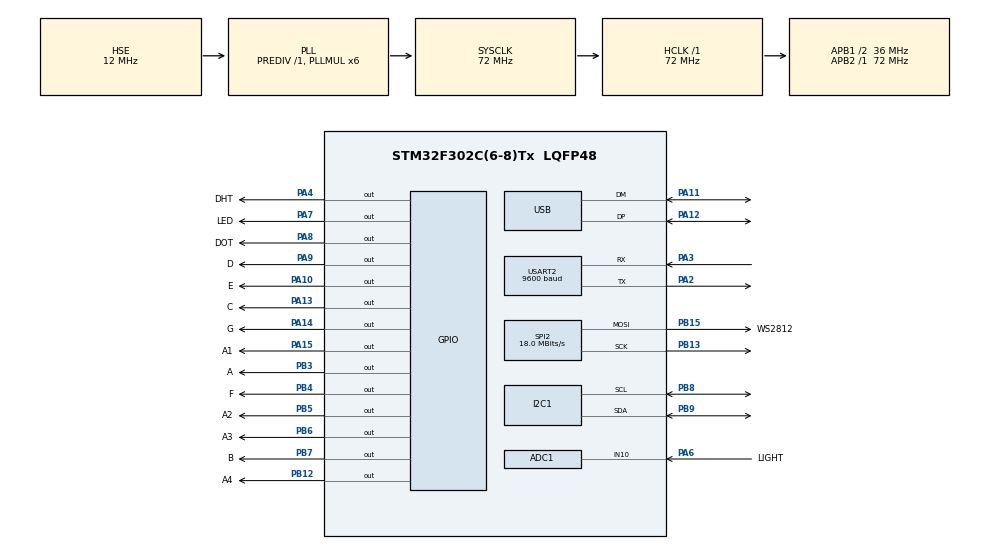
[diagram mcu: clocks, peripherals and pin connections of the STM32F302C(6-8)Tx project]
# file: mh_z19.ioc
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ADC1.Channel-0\#ChannelRegularConversion=ADC_CHANNEL_10
ADC1.NbrOfConversionFlag=1
ADC1.Offset-0\#ChannelRegularConversion=0
ADC1.OffsetNumber-0\#ChannelRegularConversion=ADC_OFFSET_NONE
ADC1.Rank-0\#ChannelRegularConversion=1
ADC1.SamplingTime-0\#ChannelRegularConversion=ADC_SAMPLETIME_1CYCLE_5
ADC1.SamplingTimeOPAMP-0\#ChannelRegularConversion=ADC_SAMPLETIME_19CYCLES_5
ADC1.SubFamily=STM32F302x8
ADC1.master=1
Dma.Request0=SPI2_TX
Dma.Request1=USART2_TX
Dma.SPI2_TX.0.Direction=DMA_MEMORY_TO_PERIPH
Dma.SPI2_TX.0.Instance=DMA1_Channel5
Dma.SPI2_TX.0.MemDataAlignment=DMA_MDATAALIGN_BYTE
Dma.SPI2_TX.0.MemInc=DMA_MINC_ENABLE
Dma.SPI2_TX.0.Mode=DMA_NORMAL
Dma.SPI2_TX.0.PeriphDataAlignment=DMA_PDATAALIGN_BYTE
Dma.SPI2_TX.0.PeriphInc=DMA_PINC_DISABLE
Dma.SPI2_TX.0.Priority=DMA_PRIORITY_LOW
Dma.USART2_TX.1.Direction=DMA_MEMORY_TO_PERIPH
Dma.USART2_TX.1.Instance=DMA1_Channel7
Dma.USART2_TX.1.MemDataAlignment=DMA_MDATAALIGN_BYTE
Dma.USART2_TX.1.MemInc=DMA_MINC_ENABLE
Dma.USART2_TX.1.Mode=DMA_NORMAL
Dma.USART2_TX.1.PeriphDataAlignment=DMA_PDATAALIGN_BYTE
Dma.USART2_TX.1.PeriphInc=DMA_PINC_DISABLE
Dma.USART2_TX.1.Priority=DMA_PRIORITY_LOW
I2C1.Timing=0x00201D2B
Mcu.Family=STM32F3
Mcu.Name=STM32F302C(6-8)Tx
Mcu.Package=LQFP48
NVIC.DMA1_Channel5_IRQn=true\:0\:0\:false\:false\:true\:false\:true\:true
NVIC.DMA1_Channel7_IRQn=true\:0\:0\:false\:false\:true\:false\:true\:true
NVIC.PriorityGroup=NVIC_PRIORITYGROUP_4
NVIC.USB_LP_CAN_RX0_IRQn=true\:0\:0\:false\:false\:true\:false\:true\:true
PA10.GPIO_Label=E
PA10.GPIO_ModeDefaultOutputPP=GPIO_MODE_OUTPUT_OD
PA10.GPIO_Speed=GPIO_SPEED_FREQ_HIGH
PA10.PinState=GPIO_PIN_SET
PA10.Signal=GPIO_Output
PA11.Mode=Device
PA11.Signal=USB_DM
PA12.Mode=Device
PA12.Signal=USB_DP
PA13.GPIO_Label=C
PA13.GPIO_ModeDefaultOutputPP=GPIO_MODE_OUTPUT_OD
PA13.PinState=GPIO_PIN_SET
PA13.Signal=GPIO_Output
PA14.GPIO_Label=G
PA14.GPIO_ModeDefaultOutputPP=GPIO_MODE_OUTPUT_OD
PA14.PinState=GPIO_PIN_SET
PA14.Signal=GPIO_Output
PA15.GPIO_Label=A1
PA15.GPIO_ModeDefaultOutputPP=GPIO_MODE_OUTPUT_OD
PA15.GPIO_Speed=GPIO_SPEED_FREQ_HIGH
PA15.PinState=GPIO_PIN_SET
PA15.Signal=GPIO_Output
PA2.Mode=Asynchronous
PA2.Signal=USART2_TX
PA3.Mode=Asynchronous
PA3.Signal=USART2_RX
PA4.GPIO_Label=DHT
PA4.GPIO_ModeDefaultOutputPP=GPIO_MODE_OUTPUT_OD
PA4.Signal=GPIO_Output
PA6.GPIO_Label=LIGHT
PA6.Signal=ADCx_IN10
PA7.GPIO_Label=LED
PA7.Signal=GPIO_Output
PA8.GPIO_Label=DOT
PA8.GPIO_ModeDefaultOutputPP=GPIO_MODE_OUTPUT_OD
PA8.GPIO_Speed=GPIO_SPEED_FREQ_HIGH
PA8.PinState=GPIO_PIN_SET
PA8.Signal=GPIO_Output
PA9.GPIO_Label=D
PA9.GPIO_ModeDefaultOutputPP=GPIO_MODE_OUTPUT_OD
PA9.GPIO_Speed=GPIO_SPEED_FREQ_HIGH
PA9.PinState=GPIO_PIN_SET
PA9.Signal=GPIO_Output
PB12.GPIO_Label=A4
PB12.GPIO_Speed=GPIO_SPEED_FREQ_HIGH
PB12.Signal=GPIO_Output
PB13.Mode=TX_Only_Simplex_Unidirect_Master
PB13.Signal=SPI2_SCK
PB15.GPIO_Label=WS2812
PB15.Mode=TX_Only_Simplex_Unidirect_Master
PB15.Signal=SPI2_MOSI
PB3.GPIO_Label=A
PB3.GPIO_ModeDefaultOutputPP=GPIO_MODE_OUTPUT_OD
PB3.GPIO_Speed=GPIO_SPEED_FREQ_HIGH
PB3.PinState=GPIO_PIN_SET
PB3.Signal=GPIO_Output
PB4.GPIO_Label=F
PB4.GPIO_ModeDefaultOutputPP=GPIO_MODE_OUTPUT_OD
PB4.GPIO_Speed=GPIO_SPEED_FREQ_HIGH
PB4.PinState=GPIO_PIN_SET
PB4.Signal=GPIO_Output
PB5.GPIO_Label=A2
PB5.GPIO_ModeDefaultOutputPP=GPIO_MODE_OUTPUT_OD
PB5.GPIO_Speed=GPIO_SPEED_FREQ_HIGH
PB5.PinState=GPIO_PIN_SET
PB5.Signal=GPIO_Output
PB6.GPIO_Label=A3
PB6.GPIO_ModeDefaultOutputPP=GPIO_MODE_OUTPUT_OD
PB6.GPIO_Speed=GPIO_SPEED_FREQ_HIGH
PB6.PinState=GPIO_PIN_SET
PB6.Signal=GPIO_Output
PB7.GPIO_Label=B
PB7.GPIO_ModeDefaultOutputPP=GPIO_MODE_OUTPUT_OD
PB7.GPIO_Speed=GPIO_SPEED_FREQ_HIGH
PB7.PinState=GPIO_PIN_SET
PB7.Signal=GPIO_Output
PB8.GPIO_Pu=GPIO_PULLUP
PB8.Mode=I2C
PB8.Signal=I2C1_SCL
PB9.GPIO_Pu=GPIO_PULLUP
PB9.Mode=I2C
PB9.Signal=I2C1_SDA
PF0-OSC_IN.Mode=HSE-External-Oscillator
PF0-OSC_IN.Signal=RCC_OSC_IN
PF1-OSC_OUT.Mode=HSE-External-Oscillator
PF1-OSC_OUT.Signal=RCC_OSC_OUT
ProjectManager.HeapSize=0x200
ProjectManager.StackSize=0x400
ProjectManager.TargetToolchain=Makefile
RCC.AHBFreq_Value=72000000
RCC.APB1CLKDivider=RCC_HCLK_DIV2
RCC.APB1Freq_Value=36000000
RCC.APB1TimFreq_Value=72000000
RCC.APB2Freq_Value=72000000
RCC.APB2TimFreq_Value=72000000
RCC.CortexFreq_Value=72000000
RCC.HCLKFreq_Value=72000000
RCC.HSE_VALUE=12000000
RCC.HSI_VALUE=8000000
RCC.LSE_VALUE=32768
RCC.PLLMUL=RCC_PLL_MUL6
RCC.PRESCALERUSB=RCC_USBCLKSOURCE_PLL_DIV1_5
RCC.SYSCLKFreq_VALUE=72000000
RCC.SYSCLKSourceVirtual=RCC_SYSCLKSOURCE_PLLCLK
RCC.USBFreq_Value=48000000
SH.ADCx_IN10.0=ADC1_IN10,IN10-Single-Ended
SPI2.BaudRatePrescaler=SPI_BAUDRATEPRESCALER_2
SPI2.CalculateBaudRate=18.0 MBits/s
SPI2.DataSize=SPI_DATASIZE_8BIT
SPI2.Direction=SPI_DIRECTION_2LINES
SPI2.Mode=SPI_MODE_MASTER
SPI2.NSSPMode=SPI_NSS_PULSE_DISABLE
SPI2.VirtualType=VM_MASTER
TIM15.Prescaler=19
USART2.BaudRate=9600
USART2.VirtualMode-Asynchronous=VM_ASYNC
USB_DEVICE.CLASS_NAME_FS=CDC
USB_DEVICE.VirtualMode=Cdc
USB_DEVICE.VirtualModeFS=Cdc_FS
VP_CRC_VS_CRC.Mode=CRC_Activate
VP_TIM15_VS_ClockSourceINT.Mode=Internal
VP_USB_DEVICE_VS_USB_DEVICE_CDC_FS.Mode=CDC_FS
board=custom

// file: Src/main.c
/* USER CODE BEGIN Header */
/**
  ******************************************************************************
  * @file           : main.c
  * @brief          : Main program body
  ******************************************************************************
  * @attention
  *
  * <h2><center>&copy; Copyright (c) 2020 STMicroelectronics.
  * All rights reserved.</center></h2>
  *
  * This software component is licensed by ST under BSD 3-Clause license,
  * the "License"; You may not use this file except in compliance with the
  * License. You may obtain a copy of the License at:
  *                        opensource.org/licenses/BSD-3-Clause
  *
  ******************************************************************************
  */
/* USER CODE END Header */
#include "main.h"
#include "usb_device.h"

/* USER CODE BEGIN Includes */
extern void loop(void);
/* USER CODE END Includes */

ADC_HandleTypeDef hadc1;

CRC_HandleTypeDef hcrc;

I2C_HandleTypeDef hi2c1;

SPI_HandleTypeDef hspi2;
DMA_HandleTypeDef hdma_spi2_tx;

TIM_HandleTypeDef htim15;

UART_HandleTypeDef huart2;
DMA_HandleTypeDef hdma_usart2_tx;

void SystemClock_Config(void);
static void MX_GPIO_Init(void);
static void MX_DMA_Init(void);
static void MX_I2C1_Init(void);
static void MX_SPI2_Init(void);
static void MX_USART2_UART_Init(void);
static void MX_ADC1_Init(void);
static void MX_TIM15_Init(void);
static void MX_CRC_Init(void);

int main(void)
{

  /* MCU Configuration--------------------------------------------------------*/

  /* Reset of all peripherals, Initializes the Flash interface and the Systick. */
  HAL_Init();

  /* Configure the system clock */
  SystemClock_Config();

  /* Initialize all configured peripherals */
  MX_GPIO_Init();
  MX_DMA_Init();
  MX_I2C1_Init();
  MX_SPI2_Init();
  MX_USART2_UART_Init();
  MX_ADC1_Init();
  MX_TIM15_Init();
  MX_CRC_Init();
  MX_USB_DEVICE_Init();

  /* Infinite loop */
  /* USER CODE BEGIN WHILE */
  while (1)
  {
    loop();
    /* USER CODE END WHILE */

  }
}

void SystemClock_Config(void)
{
  RCC_OscInitTypeDef RCC_OscInitStruct = {0};
  RCC_ClkInitTypeDef RCC_ClkInitStruct = {0};
  RCC_PeriphCLKInitTypeDef PeriphClkInit = {0};

  /** Initializes the RCC Oscillators according to the specified parameters
  * in the RCC_OscInitTypeDef structure.
  */
  RCC_OscInitStruct.OscillatorType = RCC_OSCILLATORTYPE_HSI|RCC_OSCILLATORTYPE_HSE;
  RCC_OscInitStruct.HSEState = RCC_HSE_ON;
  RCC_OscInitStruct.HSEState = RCC_HSE_ON;
  RCC_OscInitStruct.HSEPredivValue = RCC_HSE_PREDIV_DIV1;
  RCC_OscInitStruct.HSIState = RCC_HSI_ON;
  RCC_OscInitStruct.HSICalibrationValue = RCC_HSICALIBRATION_DEFAULT;
  RCC_OscInitStruct.PLL.PLLState = RCC_PLL_ON;
  RCC_OscInitStruct.PLL.PLLSource = RCC_PLLSOURCE_HSE;
  RCC_OscInitStruct.PLL.PLLMUL = RCC_PLL_MUL6;
  if (HAL_RCC_OscConfig(&RCC_OscInitStruct) != HAL_OK)
  {
    Error_Handler();
  }

  /** Initializes the CPU, AHB and APB buses clocks
  */
  RCC_ClkInitStruct.ClockType = RCC_CLOCKTYPE_HCLK|RCC_CLOCKTYPE_SYSCLK
                              |RCC_CLOCKTYPE_PCLK1|RCC_CLOCKTYPE_PCLK2;
  RCC_ClkInitStruct.SYSCLKSource = RCC_SYSCLKSOURCE_PLLCLK;
  RCC_ClkInitStruct.AHBCLKDivider = RCC_SYSCLK_DIV1;
  RCC_ClkInitStruct.APB1CLKDivider = RCC_HCLK_DIV2;
  RCC_ClkInitStruct.APB2CLKDivider = RCC_HCLK_DIV1;

  if (HAL_RCC_ClockConfig(&RCC_ClkInitStruct, FLASH_LATENCY_2) != HAL_OK)
  {
    Error_Handler();
  }
  PeriphClkInit.PeriphClockSelection = RCC_PERIPHCLK_USB|RCC_PERIPHCLK_I2C1
                              |RCC_PERIPHCLK_TIM15|RCC_PERIPHCLK_ADC1;
  PeriphClkInit.I2c1ClockSelection = RCC_I2C1CLKSOURCE_HSI;
  PeriphClkInit.USBClockSelection = RCC_USBCLKSOURCE_PLL_DIV1_5;
  PeriphClkInit.Tim15ClockSelection = RCC_TIM15CLK_HCLK;
  PeriphClkInit.Adc1ClockSelection = RCC_ADC1PLLCLK_DIV1;

  if (HAL_RCCEx_PeriphCLKConfig(&PeriphClkInit) != HAL_OK)
  {
    Error_Handler();
  }
}

static void MX_ADC1_Init(void)
{

  ADC_ChannelConfTypeDef sConfig = {0};

  /** Common config
  */
  hadc1.Instance = ADC1;
  hadc1.Init.ClockPrescaler = ADC_CLOCK_ASYNC_DIV1;
  hadc1.Init.Resolution = ADC_RESOLUTION_12B;
  hadc1.Init.ScanConvMode = ADC_SCAN_DISABLE;
  hadc1.Init.ContinuousConvMode = DISABLE;
  hadc1.Init.DiscontinuousConvMode = DISABLE;
  hadc1.Init.ExternalTrigConvEdge = ADC_EXTERNALTRIGCONVEDGE_NONE;
  hadc1.Init.ExternalTrigConv = ADC_SOFTWARE_START;
  hadc1.Init.DataAlign = ADC_DATAALIGN_RIGHT;
  hadc1.Init.NbrOfConversion = 1;
  hadc1.Init.DMAContinuousRequests = DISABLE;
  hadc1.Init.EOCSelection = ADC_EOC_SINGLE_CONV;
  hadc1.Init.LowPowerAutoWait = DISABLE;
  hadc1.Init.Overrun = ADC_OVR_DATA_OVERWRITTEN;
  if (HAL_ADC_Init(&hadc1) != HAL_OK)
  {
    Error_Handler();
  }

  /** Configure Regular Channel
  */
  sConfig.Channel = ADC_CHANNEL_10;
  sConfig.Rank = ADC_REGULAR_RANK_1;
  sConfig.SingleDiff = ADC_SINGLE_ENDED;
  sConfig.SamplingTime = ADC_SAMPLETIME_1CYCLE_5;
  sConfig.OffsetNumber = ADC_OFFSET_NONE;
  sConfig.Offset = 0;
  if (HAL_ADC_ConfigChannel(&hadc1, &sConfig) != HAL_OK)
  {
    Error_Handler();
  }

}

static void MX_CRC_Init(void)
{

  hcrc.Instance = CRC;
  hcrc.Init.DefaultPolynomialUse = DEFAULT_POLYNOMIAL_ENABLE;
  hcrc.Init.DefaultInitValueUse = DEFAULT_INIT_VALUE_ENABLE;
  hcrc.Init.InputDataInversionMode = CRC_INPUTDATA_INVERSION_NONE;
  hcrc.Init.OutputDataInversionMode = CRC_OUTPUTDATA_INVERSION_DISABLE;
  hcrc.InputDataFormat = CRC_INPUTDATA_FORMAT_BYTES;
  if (HAL_CRC_Init(&hcrc) != HAL_OK)
  {
    Error_Handler();
  }

}

static void MX_I2C1_Init(void)
{

  hi2c1.Instance = I2C1;
  hi2c1.Init.Timing = 0x00201D2B;
  hi2c1.Init.OwnAddress1 = 0;
  hi2c1.Init.AddressingMode = I2C_ADDRESSINGMODE_7BIT;
  hi2c1.Init.DualAddressMode = I2C_DUALADDRESS_DISABLE;
  hi2c1.Init.OwnAddress2 = 0;
  hi2c1.Init.OwnAddress2Masks = I2C_OA2_NOMASK;
  hi2c1.Init.GeneralCallMode = I2C_GENERALCALL_DISABLE;
  hi2c1.Init.NoStretchMode = I2C_NOSTRETCH_DISABLE;
  if (HAL_I2C_Init(&hi2c1) != HAL_OK)
  {
    Error_Handler();
  }

  /** Configure Analogue filter
  */
  if (HAL_I2CEx_ConfigAnalogFilter(&hi2c1, I2C_ANALOGFILTER_ENABLE) != HAL_OK)
  {
    Error_Handler();
  }

  /** Configure Digital filter
  */
  if (HAL_I2CEx_ConfigDigitalFilter(&hi2c1, 0) != HAL_OK)
  {
    Error_Handler();
  }

}

static void MX_SPI2_Init(void)
{

  /* SPI2 parameter configuration*/
  hspi2.Instance = SPI2;
  hspi2.Init.Mode = SPI_MODE_MASTER;
  hspi2.Init.Direction = SPI_DIRECTION_2LINES;
  hspi2.Init.DataSize = SPI_DATASIZE_8BIT;
  hspi2.Init.CLKPolarity = SPI_POLARITY_LOW;
  hspi2.Init.CLKPhase = SPI_PHASE_1EDGE;
  hspi2.Init.NSS = SPI_NSS_SOFT;
  hspi2.Init.BaudRatePrescaler = SPI_BAUDRATEPRESCALER_2;
  hspi2.Init.FirstBit = SPI_FIRSTBIT_MSB;
  hspi2.Init.TIMode = SPI_TIMODE_DISABLE;
  hspi2.Init.CRCCalculation = SPI_CRCCALCULATION_DISABLE;
  hspi2.Init.CRCPolynomial = 7;
  hspi2.Init.CRCLength = SPI_CRC_LENGTH_DATASIZE;
  hspi2.Init.NSSPMode = SPI_NSS_PULSE_DISABLE;
  if (HAL_SPI_Init(&hspi2) != HAL_OK)
  {
    Error_Handler();
  }

}

static void MX_TIM15_Init(void)
{

  TIM_ClockConfigTypeDef sClockSourceConfig = {0};
  TIM_MasterConfigTypeDef sMasterConfig = {0};

  htim15.Instance = TIM15;
  htim15.Init.Prescaler = 19;
  htim15.Init.CounterMode = TIM_COUNTERMODE_UP;
  htim15.Init.Period = 65535;
  htim15.Init.ClockDivision = TIM_CLOCKDIVISION_DIV1;
  htim15.Init.RepetitionCounter = 0;
  htim15.Init.AutoReloadPreload = TIM_AUTORELOAD_PRELOAD_DISABLE;
  if (HAL_TIM_Base_Init(&htim15) != HAL_OK)
  {
    Error_Handler();
  }
  sClockSourceConfig.ClockSource = TIM_CLOCKSOURCE_INTERNAL;
  if (HAL_TIM_ConfigClockSource(&htim15, &sClockSourceConfig) != HAL_OK)
  {
    Error_Handler();
  }
  sMasterConfig.MasterOutputTrigger = TIM_TRGO_RESET;
  sMasterConfig.MasterSlaveMode = TIM_MASTERSLAVEMODE_DISABLE;
  if (HAL_TIMEx_MasterConfigSynchronization(&htim15, &sMasterConfig) != HAL_OK)
  {
    Error_Handler();
  }

}

static void MX_USART2_UART_Init(void)
{

  huart2.Instance = USART2;
  huart2.Init.BaudRate = 9600;
  huart2.Init.WordLength = UART_WORDLENGTH_8B;
  huart2.Init.StopBits = UART_STOPBITS_1;
  huart2.Init.Parity = UART_PARITY_NONE;
  huart2.Init.Mode = UART_MODE_TX_RX;
  huart2.Init.HwFlowCtl = UART_HWCONTROL_NONE;
  huart2.Init.OverSampling = UART_OVERSAMPLING_16;
  huart2.Init.OneBitSampling = UART_ONE_BIT_SAMPLE_DISABLE;
  huart2.AdvancedInit.AdvFeatureInit = UART_ADVFEATURE_NO_INIT;
  if (HAL_UART_Init(&huart2) != HAL_OK)
  {
    Error_Handler();
  }

}

static void MX_DMA_Init(void)
{

  /* DMA controller clock enable */
  __HAL_RCC_DMA1_CLK_ENABLE();

  /* DMA interrupt init */
  /* DMA1_Channel5_IRQn interrupt configuration */
  HAL_NVIC_SetPriority(DMA1_Channel5_IRQn, 0, 0);
  HAL_NVIC_EnableIRQ(DMA1_Channel5_IRQn);
  /* DMA1_Channel7_IRQn interrupt configuration */
  HAL_NVIC_SetPriority(DMA1_Channel7_IRQn, 0, 0);
  HAL_NVIC_EnableIRQ(DMA1_Channel7_IRQn);

}

static void MX_GPIO_Init(void)
{
  GPIO_InitTypeDef GPIO_InitStruct = {0};

  /* GPIO Ports Clock Enable */
  __HAL_RCC_GPIOF_CLK_ENABLE();
  __HAL_RCC_GPIOA_CLK_ENABLE();
  __HAL_RCC_GPIOB_CLK_ENABLE();

  /*Configure GPIO pin Output Level */
  HAL_GPIO_WritePin(GPIOA, DHT_Pin|LED_Pin, GPIO_PIN_RESET);

  /*Configure GPIO pin Output Level */
  HAL_GPIO_WritePin(A4_GPIO_Port, A4_Pin, GPIO_PIN_RESET);

  /*Configure GPIO pin Output Level */
  HAL_GPIO_WritePin(GPIOA, DOT_Pin|D_Pin|E_Pin|C_Pin
                          |G_Pin|A1_Pin, GPIO_PIN_SET);

  /*Configure GPIO pin Output Level */
  HAL_GPIO_WritePin(GPIOB, A_Pin|F_Pin|A2_Pin|A3_Pin
                          |B_Pin, GPIO_PIN_SET);

  /*Configure GPIO pins : DHT_Pin C_Pin G_Pin */
  GPIO_InitStruct.Pin = DHT_Pin|C_Pin|G_Pin;
  GPIO_InitStruct.Mode = GPIO_MODE_OUTPUT_OD;
  GPIO_InitStruct.Pull = GPIO_NOPULL;
  GPIO_InitStruct.Speed = GPIO_SPEED_FREQ_LOW;
  HAL_GPIO_Init(GPIOA, &GPIO_InitStruct);

  /*Configure GPIO pin : LED_Pin */
  GPIO_InitStruct.Pin = LED_Pin;
  GPIO_InitStruct.Mode = GPIO_MODE_OUTPUT_PP;
  GPIO_InitStruct.Pull = GPIO_NOPULL;
  GPIO_InitStruct.Speed = GPIO_SPEED_FREQ_LOW;
  HAL_GPIO_Init(LED_GPIO_Port, &GPIO_InitStruct);

  /*Configure GPIO pin : A4_Pin */
  GPIO_InitStruct.Pin = A4_Pin;
  GPIO_InitStruct.Mode = GPIO_MODE_OUTPUT_PP;
  GPIO_InitStruct.Pull = GPIO_NOPULL;
  GPIO_InitStruct.Speed = GPIO_SPEED_FREQ_HIGH;
  HAL_GPIO_Init(A4_GPIO_Port, &GPIO_InitStruct);

  /*Configure GPIO pins : DOT_Pin D_Pin E_Pin A1_Pin */
  GPIO_InitStruct.Pin = DOT_Pin|D_Pin|E_Pin|A1_Pin;
  GPIO_InitStruct.Mode = GPIO_MODE_OUTPUT_OD;
  GPIO_InitStruct.Pull = GPIO_NOPULL;
  GPIO_InitStruct.Speed = GPIO_SPEED_FREQ_HIGH;
  HAL_GPIO_Init(GPIOA, &GPIO_InitStruct);

  /*Configure GPIO pins : A_Pin F_Pin A2_Pin A3_Pin
                           B_Pin */
  GPIO_InitStruct.Pin = A_Pin|F_Pin|A2_Pin|A3_Pin
                          |B_Pin;
  GPIO_InitStruct.Mode = GPIO_MODE_OUTPUT_OD;
  GPIO_InitStruct.Pull = GPIO_NOPULL;
  GPIO_InitStruct.Speed = GPIO_SPEED_FREQ_HIGH;
  HAL_GPIO_Init(GPIOB, &GPIO_InitStruct);

}

void Error_Handler(void)
{
  __disable_irq();
  while (1)
  {
  }
}
